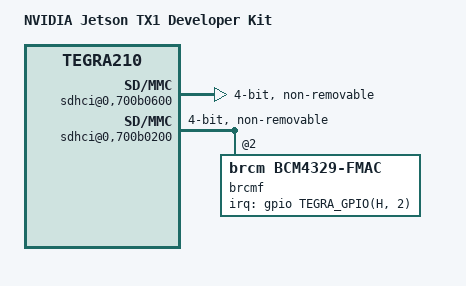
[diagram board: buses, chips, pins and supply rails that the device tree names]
/dts-v1/;

#include "tegra210-p2180.dtsi"
#include "tegra210-p2597.dtsi"

/ {
	model = "NVIDIA Jetson TX1 Developer Kit";
	compatible = "nvidia,p2371-2180", "nvidia,tegra210";

	chosen {
		xen,dom0-bootargs = "console=ttyS0,115200 earlycon=xenboot psci=enable rw ignore_loglevel clk_ignore_unused drm.atomic=1 firmware_class.path=/vendor/firmware kern_guid=%U no_console_suspend root=/dev/mmcblk0p1 rootwait";
		xen,xen-bootargs = "dom0_mem=512M loglvl=all dtuart=/serial@0,70006000";
	 };

	 module@0 {
		compatible = "multiboot,kernel", "multiboot,module";
		reg = <0 0 0 0>;
	 };

  /* eMMC */
  sdhci@0,700b0600 {
    status = "okay";
    bus-width = <4>;
    non-removable;
  };

  /* MMC/SDIO bus for wifi */
  sdhci@0,700b0200 {
    status = "okay";

    power-gpios = <&gpio TEGRA_GPIO(H, 0) GPIO_ACTIVE_HIGH>;
    bus-width = <4>;

    keep-power-in-suspend;
    non-removable;

    /* just the wifi section? */
    brcmf: brcmf@2 {
        status = "okay";
        compatible = "brcm,bcm4329-fmac";

        interrupt-parent = <&gpio>;
        interrupts = <TEGRA_GPIO(H, 2) 0x14>;
        interrupt-names = "host-wake";
    };
  };
};
